VERSION "_"

NS_ :

BS_:

BU_: node

VAL_TABLE_ enum 0 "value_0" 1 "value_1" 2 "value_2" 3 "value_3";

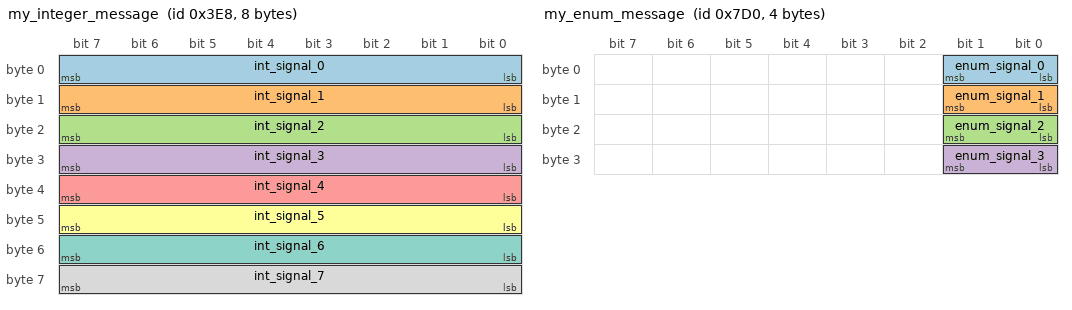
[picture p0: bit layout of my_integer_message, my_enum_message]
BO_ 1000 my_integer_message : 8 node
 SG_ int_signal_0 : 0|8@1+ (1,0) [0|255] "" Vector__XXX
 SG_ int_signal_1 : 8|8@1+ (1,0) [0|255] "" Vector__XXX
 SG_ int_signal_2 : 16|8@1+ (1,0) [0|255] "" Vector__XXX
 SG_ int_signal_3 : 24|8@1+ (1,0) [0|255] "" Vector__XXX
 SG_ int_signal_4 : 32|8@1+ (1,0) [0|255] "" Vector__XXX
 SG_ int_signal_5 : 40|8@1+ (1,0) [0|255] "" Vector__XXX
 SG_ int_signal_6 : 48|8@1+ (1,0) [0|255] "" Vector__XXX
 SG_ int_signal_7 : 56|8@1+ (1,0) [0|255] "" Vector__XXX

BO_ 2000 my_enum_message : 4 node
 SG_ enum_signal_0 : 0|2@1+ (1,0) [0|3] "" Vector__XXX
 SG_ enum_signal_1 : 8|2@1+ (1,0) [0|3] "" Vector__XXX
 SG_ enum_signal_2 : 16|2@1+ (1,0) [0|3] "" Vector__XXX
 SG_ enum_signal_3 : 24|2@1+ (1,0) [0|3] "" Vector__XXX

VAL_ 2000 enum_signal_0 0 "value_0" 1 "value_1" 2 "value_2" 3 "value_3";
VAL_ 2000 enum_signal_1 0 "value_0" 1 "value_1" 2 "value_2" 3 "value_3";
VAL_ 2000 enum_signal_2 0 "value_0" 1 "value_1" 2 "value_2" 3 "value_3";
VAL_ 2000 enum_signal_3 0 "value_0" 1 "value_1" 2 "value_2" 3 "value_3";
